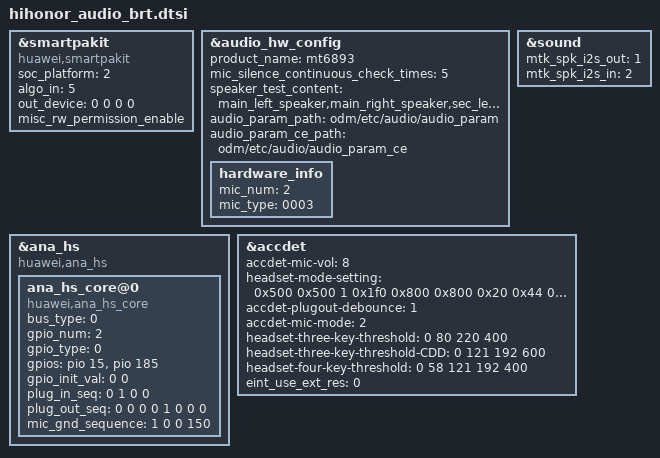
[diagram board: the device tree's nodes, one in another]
#include "fs18xx.dtsi"
#include "tas25xx.dtsi"
#include "device_boxid.dtsi"

&smartpakit {
	compatible = "huawei,smartpakit";
	/* 0 hisi, 1 qcom , 2 mtk*/
	soc_platform = <2>;
	/* algo running on: 0 codec_dsp, 1 soc_dsp, 2 smartpa_dsp, 3 simple pa(not smpartpa), 4 simple pa(with i2c) */
	algo_in = <5>;
	/* algo_in params need match out_device for smartpa.
	* Now, up to only support four pa, so out_device = <0 0 0 0>;
	* 1. This array is arranged in the following order:
	*    <0 1 2 3>
	*    <pril prir secl secr>
	* 2. This array element value is 0 or 1:
	*    smartpa: 0 speaker, 1 receiver
	*    simple pa: out_device not applicable, only set 0 to indicate pa_num
	* 3. The length of this array is variable, for example:
	*    single pa: out_device = <0>;
	*    two pa: out_device = <0 0>;
	*    four pa: out_device = <1 1 0 0>; */
	out_device = <0 0 0 0>;

	misc_rw_permission_enable;
	status = "ok";
};

&audio_hw_config {
	product_name = "mt6893";
	status = "ok";
	mic_silence_continuous_check_times = "5";
	speaker_test_content = "main_left_speaker,main_right_speaker,sec_left_speaker,sec_right_speaker";
	audio_param_path = "odm/etc/audio/audio_param";
	audio_param_ce_path = "odm/etc/audio/audio_param_ce";

	hardware_info {
		mic_num = "2";
		mic_type = "0003"; /* 0001 sub mic   0002 main mic   0004 sub mic2   0008 main mic2 */
	};
};

&ana_hs {
	compatible = "huawei,ana_hs";
	status = "ok";
	ana_hs_core@0 {
		compatible = "huawei,ana_hs_core";
		bus_type = <0>; /* 0: gpio,  1: i2c */

		/* if use gpio */
		gpio_num = <2>;
		gpio_type = <0>; // 0: SOC,  1: codec
		gpios = <&pio 15 0>,<&pio 185 0>;  /* gpio_mos_switch[H:mos to hs, L:mos to usb], gpio_mic_gnd[H:audio sbu1->mic, audio sbu2->gnd] */
		gpio_init_val = <0 0>;  /* 0 for low, 1 for high for gpio direction output */

		/* plug_in sequence */
		plug_in_seq = <
			0 1 0 0
		>;
		/* plug_out sequence */
		plug_out_seq = <
			0 0 0 0
			1 0 0 0
		>;

		/* mic_gnd_switch used gpio */
		mic_gnd_sequence = <
			1 0 0 150
		>;
		status = "ok";
	};
};

&sound {
	mtk_spk_i2s_out = <1>;
	mtk_spk_i2s_in = <2>;
};

/* accdet start */
&accdet {
	/* accdet micbias voltage: 0x09:2.85v 0x08:2.8v 0x07,
	 * 2.7v;0x05,2.5v;0x02,1.9v
	 */
	accdet-mic-vol = <8>;
	/* accdet pwm_width, pwm_thresh, fall_delay, rise_delay
	 * debounce0, debounce1, debounce3, debounce4
	 * eint pwm_width, eint pwm_thresh
	 * eint deb(debounce0, debounce1, debounce2, debounce3), inv_debounce
	 */
	headset-mode-setting = <0x500 0x500 1 0x1f0
				0x800 0x800 0x20 0x44
				0x4 0x1
				0x5 0x3 0x3 0x5 0xe>;
	accdet-plugout-debounce = <1>;
	/*1:ACC mode, 2:low cost without in bias, 6:low cost with in bias*/
	accdet-mic-mode = <2>;
	/*0--MD_MAX--UP_MAX--DW_MAX*/
	headset-three-key-threshold = <0 80 220 400>;
	headset-three-key-threshold-CDD = <0 121 192 600>;
	/*0--MD_MAX--VOICE_MAX--UP_MAX--DW_MAX*/
	headset-four-key-threshold = <0 58 121 192 400>;

	/* select VTH to 2v and 500k, use internal resitance */
	eint_use_ext_res = <0>;
	status = "okay";
};
/* accdet end */
